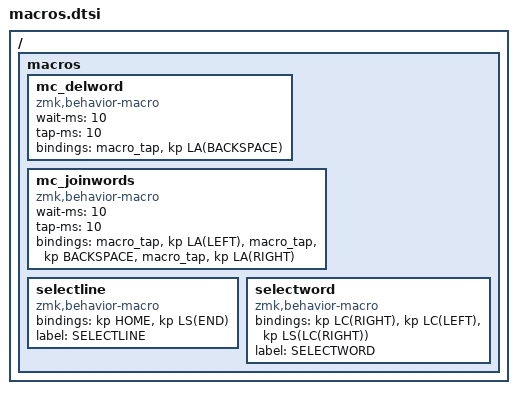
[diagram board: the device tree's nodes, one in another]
/ {
    macros {
        mc_delword: mc_delword {
            compatible = "zmk,behavior-macro";
            #binding-cells = <0>;
            wait-ms = <10>;
            tap-ms = <10>;
            bindings = <&macro_tap>, <&kp LA(BACKSPACE)>;
        };

        mc_joinwords: mc_joinwords {
            compatible = "zmk,behavior-macro";
            #binding-cells = <0>;
            wait-ms = <10>;
            tap-ms = <10>;
            bindings =
                <&macro_tap>,
                <&kp LA(LEFT)>,
                <&macro_tap>,
                <&kp BACKSPACE>,
                <&macro_tap>,
                <&kp LA(RIGHT)>;
        };

        selectline: selectline {
            compatible = "zmk,behavior-macro";
            #binding-cells = <0>;
            bindings = <&kp HOME &kp LS(END)>;
            label = "SELECTLINE";
        };

        selectword: selectword {
            compatible = "zmk,behavior-macro";
            #binding-cells = <0>;
            bindings = <&kp LC(RIGHT) &kp LC(LEFT) &kp LS(LC(RIGHT))>;
            label = "SELECTWORD";
        };
    };
};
